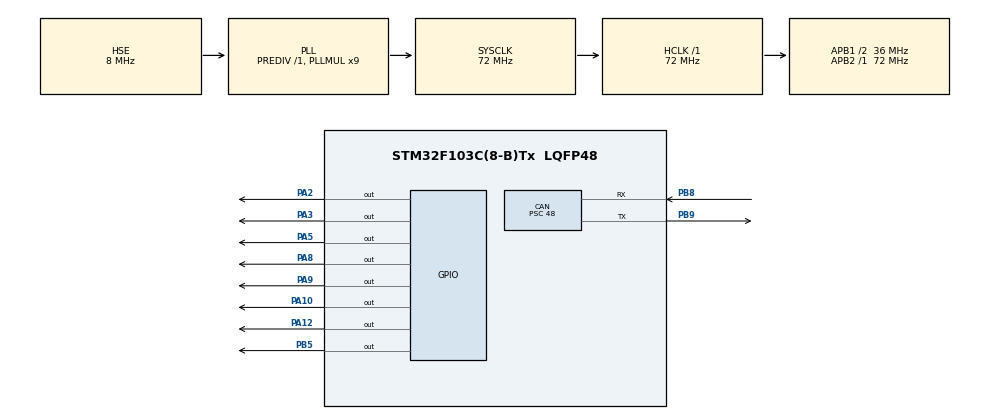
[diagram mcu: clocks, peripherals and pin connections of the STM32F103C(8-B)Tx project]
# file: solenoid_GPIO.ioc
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CAN.BS1=CAN_BS1_4TQ
CAN.BS2=CAN_BS2_3TQ
CAN.CalculateTimeBit=10666
CAN.CalculateTimeQuantum=1333.3333333333335
CAN.Prescaler=48
Mcu.Family=STM32F1
Mcu.Name=STM32F103C(8-B)Tx
Mcu.Package=LQFP48
NVIC.PriorityGroup=NVIC_PRIORITYGROUP_4
PA10.Signal=GPIO_Output
PA12.Signal=GPIO_Output
PA13.Mode=Serial_Wire
PA13.Signal=SYS_JTMS-SWDIO
PA14.Mode=Serial_Wire
PA14.Signal=SYS_JTCK-SWCLK
PA2.Signal=GPIO_Output
PA3.Signal=GPIO_Output
PA5.Signal=GPIO_Output
PA8.Signal=GPIO_Output
PA9.Signal=GPIO_Output
PB5.Signal=GPIO_Output
PB8.Mode=Master
PB8.Signal=CAN_RX
PB9.Mode=Master
PB9.Signal=CAN_TX
PC14-OSC32_IN.Mode=LSE-External-Oscillator
PC14-OSC32_IN.Signal=RCC_OSC32_IN
PC15-OSC32_OUT.Mode=LSE-External-Oscillator
PC15-OSC32_OUT.Signal=RCC_OSC32_OUT
PD0-OSC_IN.Mode=HSE-External-Oscillator
PD0-OSC_IN.Signal=RCC_OSC_IN
PD1-OSC_OUT.Mode=HSE-External-Oscillator
PD1-OSC_OUT.Signal=RCC_OSC_OUT
ProjectManager.HeapSize=0x200
ProjectManager.StackSize=0x400
ProjectManager.TargetToolchain=STM32CubeIDE
RCC.AHBFreq_Value=72000000
RCC.APB1CLKDivider=RCC_HCLK_DIV2
RCC.APB1Freq_Value=36000000
RCC.APB1TimFreq_Value=72000000
RCC.APB2Freq_Value=72000000
RCC.APB2TimFreq_Value=72000000
RCC.HCLKFreq_Value=72000000
RCC.PLLMUL=RCC_PLL_MUL9
RCC.PLLSourceVirtual=RCC_PLLSOURCE_HSE
RCC.SYSCLKFreq_VALUE=72000000
RCC.SYSCLKSource=RCC_SYSCLKSOURCE_PLLCLK
RCC.USBFreq_Value=72000000
board=custom

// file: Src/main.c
/* USER CODE BEGIN Header */
/**
  ******************************************************************************
  * @file           : main.c
  * @brief          : Main program body
  ******************************************************************************
  * @attention
  *
  * <h2><center>&copy; Copyright (c) 2019 STMicroelectronics.
  * All rights reserved.</center></h2>
  *
  * This software component is licensed by ST under BSD 3-Clause license,
  * the "License"; You may not use this file except in compliance with the
  * License. You may obtain a copy of the License at:
  *                        opensource.org/licenses/BSD-3-Clause
  *
  ******************************************************************************
  */
/* USER CODE END Header */

#include "main.h"

CAN_HandleTypeDef hcan;

void SystemClock_Config(void);
static void MX_GPIO_Init(void);
static void MX_CAN_Init(void);
/* USER CODE BEGIN PFP */
void serial_drive(uint8_t);
/* USER CODE END PFP */

int main(void)
{

  /* MCU Configuration--------------------------------------------------------*/

  /* Reset of all peripherals, Initializes the Flash interface and the Systick. */
  HAL_Init();

  /* Configure the system clock */
  SystemClock_Config();

  /* Initialize all configured peripherals */
  MX_GPIO_Init();
  MX_CAN_Init();

  /* Infinite loop */
  while (1)
  {
	  serial_drive(0b00000000);
  }
}

void serial_drive(uint8_t order) {
	uint32_t cmda = 0;
	uint32_t cmdb = 0;
	cmda |= ((0b00000111) & (order)) << 8; //set1~3
	cmda |= ((0b00001000) & (order)) << 9; //set4
	cmda |= ((0b00110000) & (order)) >> 2; //set5~6
	cmda |= ((0b01000000) & (order)) >> 1; //set7
	cmda |= ((0b0001011100101100 & (~cmda))<<16);
	cmdb |= ((0b10000000) & (order)) >> 2; //set8
	cmdb |= ((0b0000000000100000 & (~cmdb))<<16);
	GPIOA->BSRR = cmda;
	GPIOB->BSRR = cmdb;
}
void SystemClock_Config(void)
{
  RCC_OscInitTypeDef RCC_OscInitStruct = {0};
  RCC_ClkInitTypeDef RCC_ClkInitStruct = {0};

  /** Initializes the CPU, AHB and APB busses clocks
  */
  RCC_OscInitStruct.OscillatorType = RCC_OSCILLATORTYPE_HSE;
  RCC_OscInitStruct.HSEState = RCC_HSE_ON;
  RCC_OscInitStruct.HSEPredivValue = RCC_HSE_PREDIV_DIV1;
  RCC_OscInitStruct.HSIState = RCC_HSI_ON;
  RCC_OscInitStruct.PLL.PLLState = RCC_PLL_ON;
  RCC_OscInitStruct.PLL.PLLSource = RCC_PLLSOURCE_HSE;
  RCC_OscInitStruct.PLL.PLLMUL = RCC_PLL_MUL9;
  if (HAL_RCC_OscConfig(&RCC_OscInitStruct) != HAL_OK)
  {
    Error_Handler();
  }
  /** Initializes the CPU, AHB and APB busses clocks
  */
  RCC_ClkInitStruct.ClockType = RCC_CLOCKTYPE_HCLK|RCC_CLOCKTYPE_SYSCLK
                              |RCC_CLOCKTYPE_PCLK1|RCC_CLOCKTYPE_PCLK2;
  RCC_ClkInitStruct.SYSCLKSource = RCC_SYSCLKSOURCE_PLLCLK;
  RCC_ClkInitStruct.AHBCLKDivider = RCC_SYSCLK_DIV1;
  RCC_ClkInitStruct.APB1CLKDivider = RCC_HCLK_DIV2;
  RCC_ClkInitStruct.APB2CLKDivider = RCC_HCLK_DIV1;

  if (HAL_RCC_ClockConfig(&RCC_ClkInitStruct, FLASH_LATENCY_2) != HAL_OK)
  {
    Error_Handler();
  }
}

static void MX_CAN_Init(void)
{

  hcan.Instance = CAN1;
  hcan.Init.Prescaler = 48;
  hcan.Init.Mode = CAN_MODE_NORMAL;
  hcan.Init.SyncJumpWidth = CAN_SJW_1TQ;
  hcan.Init.TimeSeg1 = CAN_BS1_4TQ;
  hcan.Init.TimeSeg2 = CAN_BS2_3TQ;
  hcan.Init.TimeTriggeredMode = DISABLE;
  hcan.Init.AutoBusOff = DISABLE;
  hcan.Init.AutoWakeUp = DISABLE;
  hcan.Init.AutoRetransmission = DISABLE;
  hcan.Init.ReceiveFifoLocked = DISABLE;
  hcan.Init.TransmitFifoPriority = DISABLE;
  if (HAL_CAN_Init(&hcan) != HAL_OK)
  {
    Error_Handler();
  }

}

static void MX_GPIO_Init(void)
{
  GPIO_InitTypeDef GPIO_InitStruct = {0};

  /* GPIO Ports Clock Enable */
  __HAL_RCC_GPIOC_CLK_ENABLE();
  __HAL_RCC_GPIOD_CLK_ENABLE();
  __HAL_RCC_GPIOA_CLK_ENABLE();
  __HAL_RCC_GPIOB_CLK_ENABLE();

  /*Configure GPIO pin Output Level */
  HAL_GPIO_WritePin(GPIOA, GPIO_PIN_2|GPIO_PIN_3|GPIO_PIN_5|GPIO_PIN_8
                          |GPIO_PIN_9|GPIO_PIN_10|GPIO_PIN_12, GPIO_PIN_RESET);

  /*Configure GPIO pin Output Level */
  HAL_GPIO_WritePin(GPIOB, GPIO_PIN_5, GPIO_PIN_RESET);

  /*Configure GPIO pins : PA2 PA3 PA5 PA8
                           PA9 PA10 PA12 */
  GPIO_InitStruct.Pin = GPIO_PIN_2|GPIO_PIN_3|GPIO_PIN_5|GPIO_PIN_8
                          |GPIO_PIN_9|GPIO_PIN_10|GPIO_PIN_12;
  GPIO_InitStruct.Mode = GPIO_MODE_OUTPUT_PP;
  GPIO_InitStruct.Pull = GPIO_NOPULL;
  GPIO_InitStruct.Speed = GPIO_SPEED_FREQ_LOW;
  HAL_GPIO_Init(GPIOA, &GPIO_InitStruct);

  /*Configure GPIO pin : PB5 */
  GPIO_InitStruct.Pin = GPIO_PIN_5;
  GPIO_InitStruct.Mode = GPIO_MODE_OUTPUT_PP;
  GPIO_InitStruct.Pull = GPIO_NOPULL;
  GPIO_InitStruct.Speed = GPIO_SPEED_FREQ_LOW;
  HAL_GPIO_Init(GPIOB, &GPIO_InitStruct);

}

void Error_Handler(void)
{
}

/************************ (C) COPYRIGHT STMicroelectronics *****END OF FILE****/
